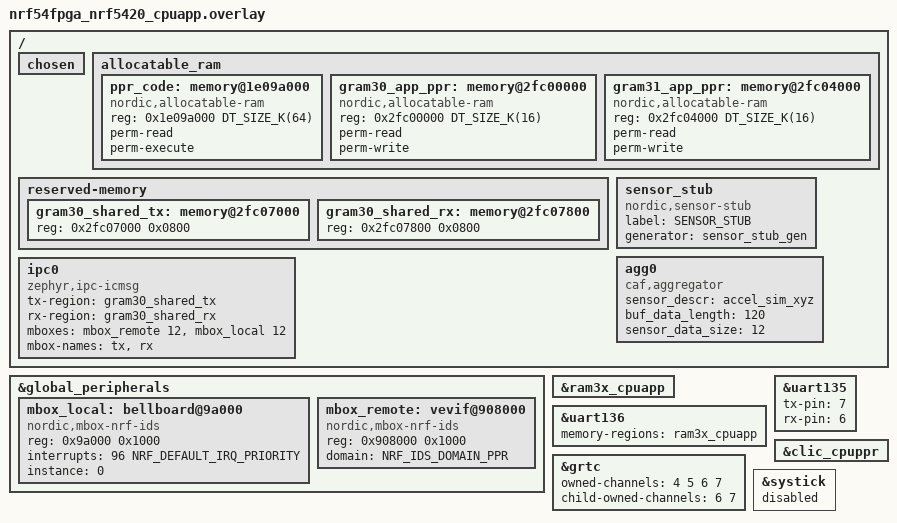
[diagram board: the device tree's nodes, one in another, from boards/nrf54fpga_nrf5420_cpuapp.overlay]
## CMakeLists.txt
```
#
# Copyright (c) 2022 Nordic Semiconductor
#
# SPDX-License-Identifier: LicenseRef-Nordic-5-Clause
#
cmake_minimum_required(VERSION 3.20.0)

set(ZEPHYR_EXTRA_MODULES ${CMAKE_CURRENT_LIST_DIR})
find_package(Zephyr REQUIRED HINTS $ENV{ZEPHYR_BASE})
project("Sensor manager sample")

target_sources(app PRIVATE src/main.c)

# Add include directory for board specific CAF def files
zephyr_include_directories(
  configuration/
  configuration/${BOARD})

add_subdirectory(src/modules)

if (CONFIG_SOC_PLATFORM_HALTIUM)
  build_secdom()
  build_sysctrl()
endif()
```

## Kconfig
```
#
# Copyright (c) 2022 Nordic Semiconductor ASA
#
# SPDX-License-Identifier: LicenseRef-Nordic-5-Clause
#

menu "Sensor manager sample"
rsource "src/modules/Kconfig"

config APP_INCLUDE_REMOTE_IMAGE
	bool "Include remote image build"
	depends on SOC_NRF5340_CPUAPP || SOC_NRF54H20_CPUAPP || SOC_NRF9230_CPUAPP
	select PARTITION_MANAGER_ENABLED if SOC_NRF5340_CPUAPP
	select BOARD_ENABLE_CPUNET if (BOARD_NRF5340DK_NRF5340_CPUAPP || BOARD_NRF5340DK_NRF5340_CPUAPP_NS)

config APP_REMOTE_BOARD
	string "The name of the board to be used by remote image"
	depends on APP_INCLUDE_REMOTE_IMAGE
	default DOMAIN_CPUNET_BOARD if (BOARD_NRF5340DK_NRF5340_CPUAPP || BOARD_NRF5340DK_NRF5340_CPUAPP_NS)
	default "nrf54h20dk_nrf54h20_cpuppr@soc1" if (BOARD_NRF54H20DK_NRF54H20_CPUAPP && HW_REVISION_SOC1)
	default "nrf9230dk_nrf9230_cpuppr" if (BOARD_NRF9230DK_NRF9230_CPUAPP)

# Disabling adding an empty net core image as we provide our own in this sample.
config NCS_SAMPLE_EMPTY_NET_CORE_CHILD_IMAGE
	bool "Add empty netcore child image"
	default n
endmenu

menu "Zephyr Kernel"
source "Kconfig.zephyr"
endmenu
```

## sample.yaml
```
sample:
  description: Sample showing CAF sensor manager usage
  name: CAF sensor manager sample
tests:
  sample.caf_sensor_manager.correctness_test:
    build_only: false
    harness: console
    platform_allow: nrf52840dk_nrf52840 nrf5340dk_nrf5340_cpuapp nrf54h20dk_nrf54h20_cpuapp@soc1 qemu_cortex_m3
    integration_platforms:
      - nrf52840dk_nrf52840
      - nrf5340dk_nrf5340_cpuapp
      - nrf54h20dk_nrf54h20_cpuapp@soc1
      - qemu_cortex_m3
    harness_config:
      type: multi_line
      ordered: true
      regex:
        - "main: Event manager initialized"
        - "main state:READY"
        - "Send sensor buffer desc address:"
        - "sensor_data_aggregator_release_buffer_event"
  sample.caf_sensor_manager.nrf54h20.fpga.correctness_test:
    build_only: false
    harness: console
    platform_allow: nrf54h20dk_nrf54h20_cpuapp@soc1
    integration_platforms:
      - nrf54h20dk_nrf54h20_cpuapp@soc1
    harness_config:
      type: multi_line
      ordered: true
      regex:
        - "main: Event manager initialized"
        - "main state:READY"
        - "Send sensor buffer desc address:"
        - "sensor_data_aggregator_release_buffer_event"
    extra_args: remote_CONFIG_EMULATOR_FPGA=y
    extra_configs:
      - CONFIG_EMULATOR_FPGA=y
  sample.caf_sensor_manager.nrf9230.fpga.correctness_test:
    build_only: false
    harness: console
    platform_allow: nrf9230dk_nrf9230_cpuapp
    integration_platforms:
      - nrf9230dk_nrf9230_cpuapp
    harness_config:
      type: multi_line
      ordered: true
      regex:
        - "main: Event manager initialized"
        - "main state:READY"
        - "Send sensor buffer desc address:"
        - "sensor_data_aggregator_release_buffer_event"
    extra_args: remote_CONFIG_EMULATOR_FPGA=y
    extra_configs:
      - CONFIG_EMULATOR_FPGA=y
  sample.caf_sensor_manager.nrf52840dk.power_consumption_test:
    build_only: true
    platform_allow: nrf52840dk_nrf52840
    integration_platforms:
      - nrf52840dk_nrf52840
    extra_args: CONFIG_SERIAL=n CONFIG_CONSOLE=n CONFIG_UART_CONSOLE=n CONFIG_LOG=n
  sample.caf_sensor_manager.multi_core.power_consumption_test:
    build_only: true
    platform_allow: nrf5340dk_nrf5340_cpuapp
    integration_platforms:
      - nrf5340dk_nrf5340_cpuapp
    extra_args: >
      CONFIG_SERIAL=n CONFIG_CONSOLE=n CONFIG_UART_CONSOLE=n CONFIG_LOG=n remote_CONFIG_SERIAL=n
      remote_CONFIG_CONSOLE=n remote_CONFIG_UART_CONSOLE=n remote_CONFIG_LOG=n
  sample.caf_sensor_manager.nrf54h20.fpga.multicore.power_consumption_test:
    build_only: true
    platform_allow: nrf54h20dk_nrf54h20_cpuapp@soc1
    integration_platforms:
      - nrf54h20dk_nrf54h20_cpuapp@soc1
    extra_args: remote_CONFIG_EMULATOR_FPGA=y remote_CONFIG_SERIAL=n remote_CONFIG_CONSOLE=n remote_CONFIG_UART_CONSOLE=n remote_CONFIG_LOG=n
    extra_configs:
      - CONFIG_EMULATOR_FPGA=y
      - CONFIG_SERIAL=n
      - CONFIG_CONSOLE=n
      - CONFIG_UART_CONSOLE=n
      - CONFIG_LOG=n
  sample.caf_sensor_manager.nrf5340dk_singlecore.power_consumption_test:
    build_only: true
    platform_allow: nrf5340dk_nrf5340_cpuapp
    integration_platforms:
      - nrf5340dk_nrf5340_cpuapp
    extra_args: >
      OVERLAY_CONFIG=boards/nrf5340dk_nrf5340_cpuapp_singlecore.conf CONFIG_SERIAL=n
      CONFIG_CONSOLE=n CONFIG_UART_CONSOLE=n CONFIG_LOG=n
      DTC_OVERLAY_FILE=boards/nrf5340dk_nrf5340_cpuapp_singlecore.overlay
  sample.caf_sensor_manager.nrf5340dk_singlecore.correctness_test:
    build_only: false
    platform_allow: nrf5340dk_nrf5340_cpuapp
    integration_platforms:
      - nrf5340dk_nrf5340_cpuapp
    extra_args: OVERLAY_CONFIG=boards/nrf5340dk_nrf5340_cpuapp_singlecore.conf
                DTC_OVERLAY_FILE=boards/nrf5340dk_nrf5340_cpuapp_singlecore.overlay
    harness: console
    harness_config:
      type: multi_line
      ordered: true
      regex:
        - "main: Event manager initialized"
        - "main state:READY"
        - "Send sensor buffer desc address:"
        - "sensor_data_aggregator_release_buffer_event"
  sample.caf_sensor_manager.nrf54h20.fpga.singlecore.correctness_test:
    build_only: false
    platform_allow: nrf54h20dk_nrf54h20_cpuapp@soc1
    integration_platforms:
      - nrf54h20dk_nrf54h20_cpuapp@soc1
    extra_args: OVERLAY_CONFIG=boards/nrf54h20dk_nrf54h20_cpuapp_soc1_singlecore.conf
                DTC_OVERLAY_FILE=boards/nrf54h20dk_nrf54h20_cpuapp_soc1_singlecore.overlay
    extra_configs:
      - CONFIG_EMULATOR_FPGA=y
    harness: console
    harness_config:
      type: multi_line
      ordered: true
      regex:
        - "main state:READY"
        - "Send sensor buffer desc address:"
        - "sensor_data_aggregator_release_buffer_event"
  sample.caf_sensor_manager.nrf9230.fpga.singlecore.correctness_test:
    build_only: false
    platform_allow: nrf9230dk_nrf9230_cpuapp
    integration_platforms:
      - nrf9230dk_nrf9230_cpuapp
    extra_args: OVERLAY_CONFIG=boards/nrf9230dk_nrf9230_cpuapp_singlecore.conf
                DTC_OVERLAY_FILE=boards/nrf9230dk_nrf9230_cpuapp_singlecore.overlay
    extra_configs:
      - CONFIG_EMULATOR_FPGA=y
    harness: console
    harness_config:
      type: multi_line
      ordered: true
      regex:
        - "main state:READY"
        - "Send sensor buffer desc address:"
        - "sensor_data_aggregator_release_buffer_event"
  sample.caf_sensor_manager.nrf54h20.multicore.power_consumption_test:
    build_only: true
    platform_allow: nrf54h20dk_nrf54h20_cpuapp@soc1
    integration_platforms:
      - nrf54h20dk_nrf54h20_cpuapp@soc1
    extra_args: remote_CONFIG_SERIAL=n remote_CONFIG_CONSOLE=n remote_CONFIG_UART_CONSOLE=n remote_CONFIG_LOG=n
    extra_configs:
      - CONFIG_SERIAL=n
      - CONFIG_CONSOLE=n
      - CONFIG_UART_CONSOLE=n
      - CONFIG_LOG=n
  sample.caf_sensor_manager.nrf54h20.singlecore.correctness_test:
    build_only: false
    platform_allow: nrf54h20dk_nrf54h20_cpuapp@soc1
    integration_platforms:
      - nrf54h20dk_nrf54h20_cpuapp@soc1
    extra_args: OVERLAY_CONFIG=boards/nrf54h20dk_nrf54h20_cpuapp_soc1_singlecore.conf
                DTC_OVERLAY_FILE=boards/nrf54h20dk_nrf54h20_cpuapp_soc1_singlecore.overlay
    harness: console
    harness_config:
      type: multi_line
      ordered: true
      regex:
        - "main state:READY"
        - "Send sensor buffer desc address:"
        - "sensor_data_aggregator_release_buffer_event"
```

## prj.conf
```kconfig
#
# Copyright (c) 2022 Nordic Semiconductor ASA
#
# SPDX-License-Identifier: LicenseRef-Nordic-5-Clause
#
################################################################################
# Application configuration

CONFIG_APP_WORKLOAD_SIM=y

CONFIG_CAF=y

CONFIG_CAF_INIT_LOG_SENSOR_EVENTS=n

CONFIG_CAF_SENSOR_DATA_AGGREGATOR_EVENTS=y

CONFIG_APP_EVENT_MANAGER=y
CONFIG_REBOOT=y
CONFIG_HEAP_MEM_POOL_SIZE=4096

# Using simulated sensor (the DK does not have built-in sensor)
CONFIG_SENSOR=y
CONFIG_SENSOR_SIM=y
CONFIG_SENSOR_STUB=n

CONFIG_WORKLOAD_SIM=y

################################################################################
# Debug configuration

CONFIG_ASSERT=y
CONFIG_RESET_ON_FATAL_ERROR=n

# Disable GPIO
CONFIG_GPIO=n

CONFIG_LOG=y
CONFIG_LOG_MODE_DEFERRED=y
```

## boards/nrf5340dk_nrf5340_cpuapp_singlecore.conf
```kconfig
#
# Copyright (c) 2022 Nordic Semiconductor ASA
#
# SPDX-License-Identifier: LicenseRef-Nordic-5-Clause
#
################################################################################

CONFIG_APP_INCLUDE_REMOTE_IMAGE=n
CONFIG_APP_REMOTE_BOARD=""

CONFIG_EVENT_MANAGER_PROXY=n
CONFIG_IPC_SERVICE=n
CONFIG_MBOX=n
CONFIG_NRF53_SYNC_RTC=n
CONFIG_OPENAMP=n

CONFIG_CAF_SENSOR_MANAGER=y
CONFIG_CAF_SENSOR_MANAGER_THREAD_STACK_SIZE=512
CONFIG_CAF_SENSOR_DATA_AGGREGATOR=y

CONFIG_SENSOR=y
```

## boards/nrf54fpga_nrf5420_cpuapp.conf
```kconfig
#
# Copyright (c) 2022 Nordic Semiconductor ASA
#
# SPDX-License-Identifier: LicenseRef-Nordic-5-Clause
#
################################################################################

CONFIG_APP_INCLUDE_REMOTE_IMAGE=y
CONFIG_APP_REMOTE_BOARD="nrf54fpga_nrf5420_cpuppr"

CONFIG_EVENT_MANAGER_PROXY=y
CONFIG_IPC_SERVICE=y
CONFIG_MBOX=y
CONFIG_MBOX_NRFX_IDS=y

CONFIG_CAF_SENSOR_DATA_AGGREGATOR_EVENTS=y

# Higher timouts are required.
CONFIG_EVENT_MANAGER_PROXY_BIND_TIMEOUT_MS=4000
CONFIG_APP_SENSOR_MANAGER_REMOTE_CORE_INITIALIZATION_TIMEOUT=10000

CONFIG_NRF_REGTOOL_TOML_CONFIG_FILES="uicr/nrf54fpga_nrf5420_cpuapp.toml"
```

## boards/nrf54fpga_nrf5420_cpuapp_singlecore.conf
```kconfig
#
# Copyright (c) 2022 Nordic Semiconductor ASA
#
# SPDX-License-Identifier: LicenseRef-Nordic-5-Clause
#
################################################################################

CONFIG_APP_INCLUDE_REMOTE_IMAGE=n
CONFIG_APP_REMOTE_BOARD=""

CONFIG_EVENT_MANAGER_PROXY=n
CONFIG_IPC_SERVICE=n
CONFIG_MBOX=n
CONFIG_OPENAMP=n
CONFIG_MBOX_NRFX_IDS=n

CONFIG_CAF_SENSOR_MANAGER=y
CONFIG_CAF_SENSOR_MANAGER_THREAD_STACK_SIZE=512
CONFIG_CAF_SENSOR_DATA_AGGREGATOR=y

CONFIG_SENSOR=y
CONFIG_SENSOR_SIM=y
```

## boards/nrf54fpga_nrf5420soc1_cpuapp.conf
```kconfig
#
# Copyright (c) 2022 Nordic Semiconductor ASA
#
# SPDX-License-Identifier: LicenseRef-Nordic-5-Clause
#
################################################################################

CONFIG_APP_INCLUDE_REMOTE_IMAGE=y
CONFIG_APP_REMOTE_BOARD="nrf54fpga_nrf5420soc1_cpuppr"

CONFIG_EVENT_MANAGER_PROXY=y
CONFIG_IPC_SERVICE=y
CONFIG_MBOX=y
CONFIG_MBOX_NRFX_IDS=y

CONFIG_CAF_SENSOR_DATA_AGGREGATOR_EVENTS=y

# Higher timouts are required.
CONFIG_EVENT_MANAGER_PROXY_BIND_TIMEOUT_MS=4000
CONFIG_APP_SENSOR_MANAGER_REMOTE_CORE_INITIALIZATION_TIMEOUT=10000

CONFIG_NRF_REGTOOL_TOML_CONFIG_FILES="uicr/nrf54fpga_nrf5420soc1_cpuapp.toml"
```

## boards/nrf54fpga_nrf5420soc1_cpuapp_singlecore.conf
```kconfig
#
# Copyright (c) 2022 Nordic Semiconductor ASA
#
# SPDX-License-Identifier: LicenseRef-Nordic-5-Clause
#
################################################################################

CONFIG_APP_INCLUDE_REMOTE_IMAGE=n
CONFIG_APP_REMOTE_BOARD=""

CONFIG_EVENT_MANAGER_PROXY=n
CONFIG_IPC_SERVICE=n
CONFIG_MBOX=n
CONFIG_OPENAMP=n
CONFIG_MBOX_NRFX_IDS=n

CONFIG_CAF_SENSOR_MANAGER=y
CONFIG_CAF_SENSOR_MANAGER_THREAD_STACK_SIZE=512
CONFIG_CAF_SENSOR_DATA_AGGREGATOR=y

CONFIG_SENSOR=y
CONFIG_SENSOR_STUB=y
```

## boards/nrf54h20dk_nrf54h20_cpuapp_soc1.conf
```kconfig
#
# Copyright (c) 2022 Nordic Semiconductor ASA
#
# SPDX-License-Identifier: LicenseRef-Nordic-5-Clause
#
################################################################################

CONFIG_APP_INCLUDE_REMOTE_IMAGE=y
CONFIG_APP_REMOTE_BOARD="nrf54h20dk_nrf54h20_cpuppr"

CONFIG_SERIAL=y
CONFIG_CONSOLE=y
CONFIG_UART_CONSOLE=y

CONFIG_EVENT_MANAGER_PROXY=y
CONFIG_IPC_SERVICE=y
CONFIG_MBOX=y
CONFIG_MBOX_NRFX_IDS=y

CONFIG_CAF_SENSOR_DATA_AGGREGATOR_EVENTS=y

# Higher timouts are required.
CONFIG_EVENT_MANAGER_PROXY_BIND_TIMEOUT_MS=4000
CONFIG_APP_SENSOR_MANAGER_REMOTE_CORE_INITIALIZATION_TIMEOUT=10000
```

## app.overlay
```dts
/*
 * Copyright (c) 2022 Nordic Semiconductor ASA
 *
 * SPDX-License-Identifier: LicenseRef-Nordic-5-Clause
 */

 / {
	agg0: agg0 {
		compatible = "caf,aggregator";
		sensor_descr = "accel_sim_xyz";
		buf_data_length = <240>;
		sensor_data_size = <24>;
		status = "okay";
	};
};
```

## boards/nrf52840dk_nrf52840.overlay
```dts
/*
 * Copyright (c) 2022 Nordic Semiconductor ASA
 *
 * SPDX-License-Identifier: LicenseRef-Nordic-5-Clause
 */

 / {
	sensor_stub: sensor_stub {
		compatible = "nordic,sensor-stub";
		label = "SENSOR_STUB";
		generator = "sensor_stub_gen";
		status = "okay";
	};

	agg0: agg0 {
		compatible = "caf,aggregator";
		sensor_descr = "accel_sim_xyz";
		buf_data_length = <240>;
		sample_size= <3>;
		status = "okay";
	};
};
```

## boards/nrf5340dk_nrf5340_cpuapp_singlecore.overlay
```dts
/*
 * Copyright (c) 2022 Nordic Semiconductor ASA
 *
 * SPDX-License-Identifier: LicenseRef-Nordic-5-Clause
 */

 /{
	agg0: agg0 {
		compatible = "caf,aggregator";
		sensor_descr = "accel_sim_xyz";
		buf_data_length = <240>;
		sample_size= <3>;
		status = "okay";
	};

	sensor_stub: sensor_stub {
		compatible = "nordic,sensor-stub";
		label = "SENSOR_STUB";
		generator = "sensor_stub_gen";
		status = "okay";
	};
};
```

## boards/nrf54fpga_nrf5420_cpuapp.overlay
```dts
/*
 * Copyright (c) 2022 Nordic Semiconductor ASA
 *
 * SPDX-License-Identifier: LicenseRef-Nordic-5-Clause
 */

/ {
	chosen {
		/delete-property/ nordic,bellboard-cpuapp;
		/delete-property/ nordic,vevif-cpuppr;
	};

	allocatable_ram {
		#address-cells = <1>;
		#size-cells = <1>;

		/* Configure PPR code region.
		 * This is done to ensure correct UICR generation.
		 */
		ppr_code: memory@1e09a000 {
			compatible = "nordic,allocatable-ram";
			reg = <0x1e09a000 DT_SIZE_K(64)>;
			perm-read;
			perm-execute;
		};

		/* Configure GRAM region.
		 * This is done to ensure correct UICR generation.
		 */
		gram30_app_ppr: memory@2fc00000 {
			compatible = "nordic,allocatable-ram";
			reg = <0x2fc00000 DT_SIZE_K(16)>;
			perm-read;
			perm-write;
		};

		/* Configure GRAM region.
		 * This is done to ensure correct UICR generation.
		 */
		gram31_app_ppr: memory@2fc04000 {
			compatible = "nordic,allocatable-ram";
			reg = <0x2fc04000 DT_SIZE_K(16)>;
			perm-read;
			perm-write;
		};
	};

	reserved-memory {
		gram30_shared_tx: memory@2fc07000 {
			reg = <0x2fc07000 0x0800>;
		};

		gram30_shared_rx: memory@2fc07800 {
			reg = <0x2fc07800 0x0800>;
		};
	};

	ipc0: ipc0 {
		compatible = "zephyr,ipc-icmsg";
		tx-region = <&gram30_shared_tx>;
		rx-region = <&gram30_shared_rx>;
		mboxes = <&mbox_remote 12>,
			 <&mbox_local  12>;
		mbox-names = "tx", "rx";
		status = "okay";
	};

	sensor_stub: sensor_stub {
		compatible = "nordic,sensor-stub";
		label = "SENSOR_STUB";
		generator = "sensor_stub_gen";
		status = "okay";
	};

	agg0: agg0 {
		compatible = "caf,aggregator";
		sensor_descr = "accel_sim_xyz";
		buf_data_length = <120>;
		sensor_data_size = <12>;
		status = "okay";
	};
};

&global_peripherals {
	/* Delete and redefine nodes with custom compatible. */
	/delete-node/ bellboard@9a000;
	/delete-node/ vevif@8c8000; // SYSCtrl
	/delete-node/ vevif@8d4000; // FLPR
	/delete-node/ vevif@908000; // PPR

	mbox_local: bellboard@9a000 {
		compatible = "nordic,mbox-nrf-ids";
		status = "okay";
		reg = <0x9a000 0x1000>;
		interrupts = <96 NRF_DEFAULT_IRQ_PRIORITY>;
		instance = <0>;
		#mbox-cells = <1>;
	};

	mbox_remote: vevif@908000 {
		compatible = "nordic,mbox-nrf-ids";
		status = "okay";
		reg = <0x908000 0x1000>;
		domain = <NRF_IDS_DOMAIN_PPR>; /* Remote vevif belong to CPU PPR */
		#mbox-cells = <1>;
	};
};

&ram3x_cpuapp {
	status = "okay";
};

&uart136 {
	status = "okay";
	memory-regions = <&ram3x_cpuapp>;
};

&uart135 {
	status = "okay";
	tx-pin = <7>;
	rx-pin = <6>;
};

&grtc {
	status = "okay";
	/* Channel 6 and 7 are owned by App and used by PPR.
	 * This is done to ensure correct UICR generation.
	 */
	owned-channels = <4 5 6 7>;
	child-owned-channels = <6 7>;
};

&clic_cpuppr {
	status = "okay";
};

&systick {
	status = "disabled";
};
```

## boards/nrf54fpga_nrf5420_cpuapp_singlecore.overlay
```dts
/*
 * Copyright (c) 2022 Nordic Semiconductor ASA
 *
 * SPDX-License-Identifier: LicenseRef-Nordic-5-Clause
 */

 /{
	sensor_sim: sensor_sim {
		compatible = "nordic,sensor-sim";
		label = "SENSOR_SIM";
		acc-signal = "wave";
	};

	agg0: agg0 {
		compatible = "caf,aggregator";
		sensor_descr = "accel_sim_xyz";
		buf_data_length = <120>;
		sensor_data_size = <24>;
		memory-region = <&gram30_agg_buf>;
		status = "okay";
	};

	agg1: agg1 {
		compatible = "caf,aggregator";
		sensor_descr = "void_test_sensor";
		buf_data_length = <80>;
		sensor_data_size = <8>;
		status = "okay";
	};

	reserved-memory {
		#address-cells = <1>;
		#size-cells = <1>;
		/* Configure memory region access. */

		gram30_agg_buf: memory@2fc00000 {
			compatible = "nordic,allocatable-mram";
			reg = <0x2fc00000 0x4000>;
			perm-read;
			perm-write;
		};
	};
};

/* ram3x_cpuapp buffer is used by App core UART driver. */
&ram3x_cpuapp {
	status = "okay";
};

&uart136 {
	status = "okay";
	memory-regions = <&ram3x_cpuapp>;
};

&grtc {
	status = "okay";
};

/* Disable systick for App core, GRTC is used as tick source. */
&systick {
		status = "disabled";
};
```

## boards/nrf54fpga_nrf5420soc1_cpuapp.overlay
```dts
/*
 * Copyright (c) 2022 Nordic Semiconductor ASA
 *
 * SPDX-License-Identifier: LicenseRef-Nordic-5-Clause
 */

/ {
	chosen {
		/delete-property/ nordic,bellboard-cpuapp;
		/delete-property/ nordic,vevif-cpuppr;
	};

	allocatable_ram {
		#address-cells = <1>;
		#size-cells = <1>;

		/* Configure PPR code region.
		 * This is done to ensure correct UICR generation.
		 */
		ppr_code: memory@1e09a000 {
			compatible = "nordic,allocatable-ram";
			reg = <0x1e09a000 DT_SIZE_K(64)>;
			perm-read;
			perm-execute;
		};

		/* Configure GRAM region.
		 * This is done to ensure correct UICR generation.
		 */
		ram30_app_ppr: memory@2fc00000 {
			compatible = "nordic,allocatable-ram";
			reg = <0x2fc00000 DT_SIZE_K(16)>;
			perm-read;
			perm-write;
		};

		/* Configure GRAM region.
		 * This is done to ensure correct UICR generation.
		 */
		ram31_app_ppr: memory@2fc04000 {
			compatible = "nordic,allocatable-ram";
			reg = <0x2fc04000 DT_SIZE_K(16)>;
			perm-read;
			perm-write;
		};
	};

	reserved-memory {
		ram31_shared_tx: memory@2fc07000 {
			reg = <0x2fc07000 0x0800>;
		};

		ram31_shared_rx: memory@2fc07800 {
			reg = <0x2fc07800 0x0800>;
		};
	};

	ipc0: ipc0 {
		compatible = "zephyr,ipc-icmsg";
		tx-region = <&ram31_shared_tx>;
		rx-region = <&ram31_shared_rx>;
		mboxes = <&mbox_remote 12>,
			 <&mbox_local  12>;
		mbox-names = "tx", "rx";
		status = "okay";
	};

	sensor_stub: sensor_stub {
		compatible = "nordic,sensor-stub";
		label = "SENSOR_STUB";
		generator = "sensor_stub_gen";
		status = "okay";
	};

	agg0: agg0 {
		compatible = "caf,aggregator";
		sensor_descr = "accel_sim_xyz";
		buf_data_length = <240>;
		sensor_data_size = <24>;
		status = "okay";
	};
};

&global_peripherals {
	/* Delete and redefine nodes with custom compatible. */
	/delete-node/ bellboard@9a000;
	/delete-node/ vevif@8c8000; // SYSCtrl
	/delete-node/ vevif@8d4000; // FLPR
	/delete-node/ vevif@908000; // PPR

	mbox_local: bellboard@9a000 {
		compatible = "nordic,mbox-nrf-ids";
		status = "okay";
		reg = <0x9a000 0x1000>;
		interrupts = <96 NRF_DEFAULT_IRQ_PRIORITY>;
		instance = <0>;
		#mbox-cells = <1>;
	};

	mbox_remote: vevif@908000 {
		compatible = "nordic,mbox-nrf-ids";
		status = "okay";
		reg = <0x908000 0x1000>;
		domain = <NRF_IDS_DOMAIN_PPR>; /* Remote vevif belong to CPU PPR */
		#mbox-cells = <1>;
	};
};

&ram3x_cpuapp {
	status = "okay";
};

&uart136 {
	status = "okay";
	memory-regions = <&ram3x_cpuapp>;
};

&uart135 {
	status = "okay";
	tx-pin = <7>;
	rx-pin = <6>;
};

&grtc {
	status = "okay";
	/* Channel 6 and 7 are owned by App and used by PPR.
	 * This is done to ensure correct UICR generation.
	 */
	owned-channels = <4 5 6 7>;
	child-owned-channels = <6 7>;
};

&clic_cpuppr {
	status = "okay";
};

&systick {
	status = "disabled";
};
```

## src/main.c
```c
/*
 * Copyright (c) 2022 Nordic Semiconductor ASA
 *
 * SPDX-License-Identifier: LicenseRef-Nordic-5-Clause
 */

#include <zephyr/kernel.h>
#include <app_event_manager.h>

#define MODULE main

#include <caf/events/module_state_event.h>
#include <zephyr/logging/log.h>

LOG_MODULE_REGISTER(MODULE);

#include "event_proxy_init.h"

#if defined(CONFIG_BOARD_NRF54H20DK_NRF54H20_CPUAPP) && \
	defined(CONFIG_APP_INCLUDE_REMOTE_IMAGE)
#define PPR_START_ADDR DT_REG_ADDR(DT_NODELABEL(ppr_code))
#include <hal/nrf_vpr.h>
#endif

void main(void)
{
#if defined(CONFIG_BOARD_NRF54H20DK_NRF54H20_CPUAPP) && \
	defined(CONFIG_APP_INCLUDE_REMOTE_IMAGE)
	/* Enable PPr core */
	nrf_vpr_initpc_set(NRF_VPR130, PPR_START_ADDR);
	nrf_vpr_cpurun_set(NRF_VPR130, true);
#endif
	int ret;

	ret = app_event_manager_init();
	if (ret) {
		LOG_ERR("Event Manager not initialized, err: %d", ret);
		__ASSERT_NO_MSG(false);
		return;
	}
	LOG_INF("Event manager initialized");

	ret = init_event_proxy("sensor_data_aggregator_event");
	if (ret) {
		LOG_ERR("Event Manager Proxy not initialized, err: %d", ret);
		__ASSERT_NO_MSG(false);
		return;
	}

	module_set_state(MODULE_STATE_READY);
}
```
